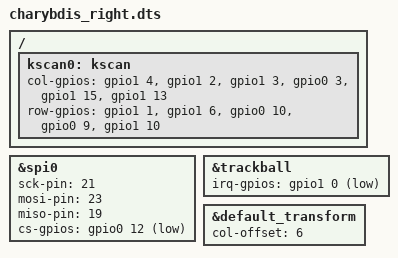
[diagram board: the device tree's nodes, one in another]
/*
 * Copyright (c) 2021 The ZMK Contributors
 *
 * SPDX-License-Identifier: MIT
 */

/dts-v1/;
#include <nordic/nrf52840_qiaa.dtsi>
#include <dt-bindings/zmk/matrix_transform.h>
#include "charybdis.dtsi"

/ {

kscan0: kscan {
  col-gpios
      = <&gpio1 4   (GPIO_ACTIVE_HIGH | GPIO_PULL_DOWN)>
      , <&gpio1 2   (GPIO_ACTIVE_HIGH | GPIO_PULL_DOWN)>
      , <&gpio1 3   (GPIO_ACTIVE_HIGH | GPIO_PULL_DOWN)>
      , <&gpio0 3   (GPIO_ACTIVE_HIGH | GPIO_PULL_DOWN)>
      , <&gpio1 15  (GPIO_ACTIVE_HIGH | GPIO_PULL_DOWN)>
      , <&gpio1 13  (GPIO_ACTIVE_HIGH | GPIO_PULL_DOWN)>
      ;
  row-gpios
      = <&gpio1 1   GPIO_ACTIVE_HIGH>
      , <&gpio1 6   GPIO_ACTIVE_HIGH>
      , <&gpio0 10  GPIO_ACTIVE_HIGH>
      , <&gpio0 9   GPIO_ACTIVE_HIGH>
      , <&gpio1 10  GPIO_ACTIVE_HIGH>
      ;
    };
};

&spi0 {
  status = "okay";
  sck-pin = <21>;
  mosi-pin = <23>;
  miso-pin = <19>;
  cs-gpios = <&gpio0 12 GPIO_ACTIVE_LOW>;
};

&trackball {
  status = "okay";
  irq-gpios = <&gpio1 0 (GPIO_ACTIVE_LOW | GPIO_PULL_UP)>;
};

&default_transform {
  col-offset = <6>;
};
